# MU3E_FULL8LANE_TYPE0_SYSTEM_SC_HUB register map
Vendor: Mu3e; Series: MU3E_FULL8LANE_TYPE0; File version: 2026.05.06
Registers are 32-bit, read-write, reset 0x0 unless marked. A register's access mark holds for its fields unless they carry their own. Offsets are from the block's base; [hi:lo] are bit positions; {n}, {i} and the like mark numbered series.

## DATA_PATH_SUBSYSTEM_DBG_MM2RUNCTRL_0_CSR — Datapath-local slave expanded below the SC-hub mm_bridge.s0 aperture. Qsys slave data_path_subsystem_dbg_mm2runctrl_0.csr is SC-hub-relative at 0x00022200 with compiled aperture size 0x00000040. Compiled Qsys module dbg_mm2runctrl_0 kind=dbg_mm2runctrl version=1.0.0 from full8lane_type0_datapath.qsys. No source SVD file was present; this peripheral is generated as an explicitly raw window. Debug MM-to-run-control adapter CSR window; no local SVD source was present.
Base 0x00022200
{0x0+4i} RAW_WORD_{i:02} (i=0..15) — Undecoded raw 32-bit word {i} in data_path_subsystem_dbg_mm2runctrl_0.csr. The compiled Qsys map exposes this word, but no semantic source SVD was present.
  [31:0] value — Raw 32-bit value for word {i}.

## DATA_PATH_SUBSYSTEM_MTS_PREPROCESSOR_0_CSR — Datapath-local slave expanded below the SC-hub mm_bridge.s0 aperture. Qsys slave data_path_subsystem_mts_preprocessor_0.csr is SC-hub-relative at 0x00024000 with compiled aperture size 0x00000020. Compiled Qsys module mts_preprocessor_0 kind=mts_preprocessor version=26.0.9.430 from full8lane_type0_datapath.qsys. Version/identity parameters: VERSION_MAJOR=26, VERSION_MINOR=0, VERSION_PATCH=2, BUILD=416, VERSION_DATE=20260416, VERSION_GIT=30068584, IP_UID=1297376080, INSTANCE_ID=0. No source SVD file was present; this peripheral is generated as an explicitly raw window. MTS preprocessor CSR window; no local SVD source was present in this worktree.
Base 0x00024000
{0x0+4i} RAW_WORD_{i:02} (i=0..7) — Undecoded raw 32-bit word {i} in data_path_subsystem_mts_preprocessor_0.csr. The compiled Qsys map exposes this word, but no semantic source SVD was present.
  [31:0] value — Raw 32-bit value for word {i}.

## DATA_PATH_SUBSYSTEM_MTS_PREPROCESSOR_1_CSR — Datapath-local slave expanded below the SC-hub mm_bridge.s0 aperture. Qsys slave data_path_subsystem_mts_preprocessor_1.csr is SC-hub-relative at 0x00028000 with compiled aperture size 0x00000020. Compiled Qsys module mts_preprocessor_1 kind=mts_preprocessor version=26.0.9.430 from full8lane_type0_datapath.qsys. Version/identity parameters: VERSION_MAJOR=26, VERSION_MINOR=0, VERSION_PATCH=2, BUILD=416, VERSION_DATE=20260416, VERSION_GIT=30068584, IP_UID=1297376080, INSTANCE_ID=0. No source SVD file was present; this peripheral is generated as an explicitly raw window. MTS preprocessor CSR window; no local SVD source was present in this worktree.
Base 0x00028000
{0x0+4i} RAW_WORD_{i:02} (i=0..7) — Undecoded raw 32-bit word {i} in data_path_subsystem_mts_preprocessor_1.csr. The compiled Qsys map exposes this word, but no semantic source SVD was present.
  [31:0] value — Raw 32-bit value for word {i}.

## DATA_PATH_SUBSYSTEM_HISTOGRAM_STATISTICS_0_HIST_BIN — Datapath-local slave expanded below the SC-hub mm_bridge.s0 aperture. Qsys slave data_path_subsystem_histogram_statistics_0.hist_bin is SC-hub-relative at 0x0002A000 with compiled aperture size 0x00000400. Compiled Qsys module histogram_statistics_0 kind=full8lane_histogram_statistics_v2 version=26.1.8.502 from full8lane_type0_datapath.qsys. Version/identity parameters: VERSION_MAJOR=26, VERSION_MINOR=1, VERSION_PATCH=8, BUILD=502, VERSION_DATE=20260502, VERSION_GIT=72231161, IP_UID=1212765012, INSTANCE_ID=0. Source SVD toolkits/infra/cmsis_svd/generic/histogram_bin_window.svd version 1.0.0. Relative 256-word histogram bin aperture.
Base 0x0002A000
{0x0+4i} WORD{i:03} ro (i=0..255) — Histogram bin word {i}.
  [31:0] value — Histogram bin value {i}.

## DATA_PATH_SUBSYSTEM_HISTOGRAM_INGRESS_BRIDGE_0_CSR — Datapath-local slave expanded below the SC-hub mm_bridge.s0 aperture. Qsys slave data_path_subsystem_histogram_ingress_bridge_0.csr is SC-hub-relative at 0x0002AC00 with compiled aperture size 0x00000010. Compiled Qsys module histogram_ingress_bridge_0 kind=histogram_ingress_bridge version=26.0.5.0506 from full8lane_type0_datapath.qsys. Version/identity parameters: VERSION_MAJOR=26, VERSION_MINOR=0, VERSION_PATCH=5, BUILD=506, VERSION_DATE=20260506, VERSION_GIT=481097348, IP_UID=1212764994, INSTANCE_ID=0. Source SVD histogram_statistics/histogram_ingress_bridge.svd version 26.0.2.0425. Relative 4-word CSR aperture for the histogram ingress selector bridge.
Base 0x0002AC00
0x00 UID ro reset 0x48495342 — Software-visible IP identifier. Default ASCII "HISB" (0x48495342).
  [31:0] value — Compile-time or integration-time UID word. Default ASCII "HISB".
0x04 META — Read-multiplexed metadata word. Write meta_sel[1:0] before reading back: 0=VERSION, 1=DATE, 2=GIT, 3=INSTANCE_ID.
  [1:0] meta_sel — Selects the META read page.
0x08 CONTROL — Requested histogram source. The bridge applies a change only once both packet streams are idle.
  [0] select_post — 0 selects pre-hit-stack traffic, 1 selects post-hit-stack traffic.
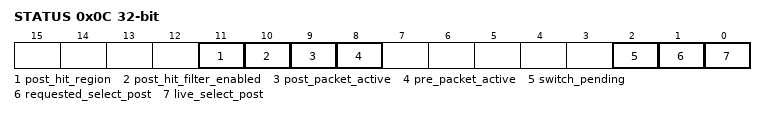
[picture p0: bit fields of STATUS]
0x0C STATUS ro — Live selector state and packet-idle visibility for safe source switching.
  [11] post_hit_region — Current post-stream parser state. 1 after a K23.7 subheader until the next frame header or trailer.
  [10] post_hit_filter_enabled — 1 when the post-hit-stack histogram tap is configured to forward only real hit words after K23.7 subheaders.
  [9] post_packet_active — 1 while the forwarded post-hit-stack path is inside a packet.
  [8] pre_packet_active — 1 while the forwarded pre-hit-stack path is inside a packet.
  [2] switch_pending — 1 while the requested source differs from the live source.
  [1] requested_select_post — Last requested histogram source from CONTROL.select_post.
  [0] live_select_post — Currently active histogram source. 0=pre, 1=post.
